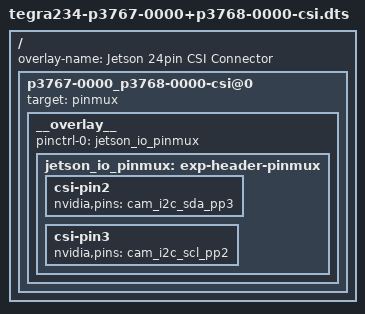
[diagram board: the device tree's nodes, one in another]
// SPDX-License-Identifier: GPL-2.0-only
// SPDX-FileCopyrightText: Copyright (c) 2023, NVIDIA CORPORATION & AFFILIATES.  All rights reserved.
/*
 * Device-tree overlay for tegra234-p3767-0000-p3768-0000 CSI Camera Connector.
 */

/dts-v1/;
/plugin/;

#include <dt-bindings/pinctrl/pinctrl-tegra.h>
#include <dt-bindings/tegra234-p3767-0000-common.h>

/ {
	overlay-name = "Jetson 24pin CSI Connector";
	compatible = JETSON_COMPATIBLE_P3768;

	p3767-0000_p3768-0000-csi@0 {
		target = <&pinmux>;
		__overlay__ {
			pinctrl-names = "default";
			pinctrl-0 = <&jetson_io_pinmux>;
			jetson_io_pinmux: exp-header-pinmux {
				csi-pin2 {
					nvidia,pins = "cam_i2c_sda_pp3";
				};
				csi-pin3 {
					nvidia,pins = "cam_i2c_scl_pp2";
				};
			};
		};
	};
};
